# PIC32CM1216MC00048 register map
Vendor: Microchip Technology; Series: PIC32CMMC00; File version: 0
CPU: CM0+ r0p0, selectable endian, MPU, no FPU, 2 interrupt priority bits
Registers are 32-bit, read-write, reset 0x0 unless marked. A register's access mark holds for its fields unless they carry their own. Offsets are from the block's base; [hi:lo] are bit positions; {n}, {i} and the like mark numbered series; 'fields as' and 'values as' point back to an identical list.

## DSU — Device Service Unit
Base 0x41002000; register names take the prefix DSU_
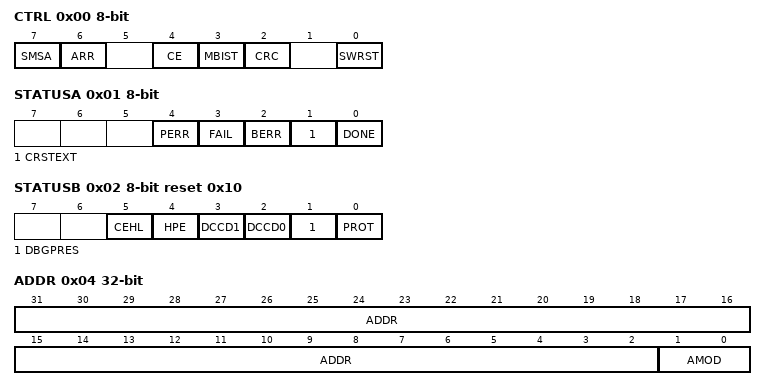
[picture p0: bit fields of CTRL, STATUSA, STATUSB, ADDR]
0x00 CTRL 8-bit wo — Control
  [7] SMSA — Start Memory Stream Access
  [6] ARR — Auxiliary Row Read
  [4] CE — Chip-Erase
  [3] MBIST — Memory built-in self-test
  [2] CRC — 32-bit Cyclic Redundancy Code
  [0] SWRST — Software Reset
0x01 STATUSA 8-bit
  [4] PERR — Protection Error
  [3] FAIL — Failure
  [2] BERR — Bus Error
  [1] CRSTEXT — CPU Reset Phase Extension
  [0] DONE
0x02 STATUSB 8-bit ro reset 0x10
  [5] CEHL — Chip Erase Hard Lock
  [4] HPE — Hot-Plugging Enable
  [3] DCCD1 — Debug Communication Channel 1 Dirty
  [2] DCCD0 — Debug Communication Channel 0 Dirty
  [1] DBGPRES — Debugger Present
  [0] PROT — Protected
0x03 STATUSC 8-bit ro
  [2:0] STATE
0x04 ADDR — Address
  [31:2] ADDR — Address
  [1:0] AMOD — Access Mode
0x08 LENGTH
  [31:2] LENGTH
0x0C DATA
{0x10+4i} DCC[{i}] (i=0..1) — Debug Communication Channel n
  [31:0] DATA
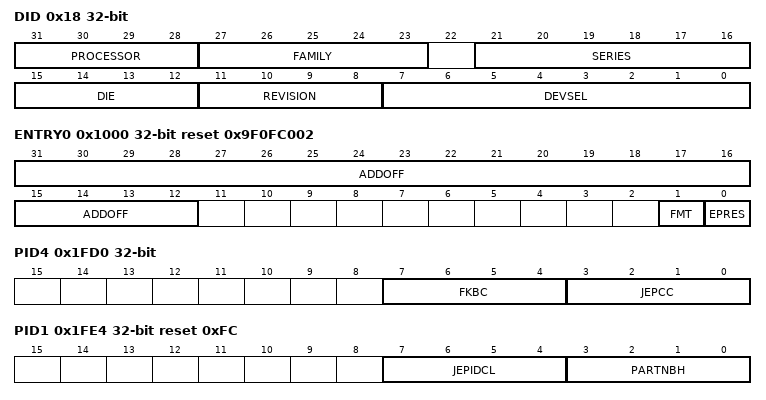
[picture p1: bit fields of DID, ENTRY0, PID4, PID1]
0x18 DID ro — Device Identification
  [31:28] PROCESSOR
    1=Cortex-M0+
  [27:23] FAMILY
    2=5V Industrial
  [21:16] SERIES
    6=MC00 (PIC32CM MC00)
  [15:12] DIE — Die Number
  [11:8] REVISION — Revision Number
  [7:0] DEVSEL — Device Select
    0=128KB_16KB_32PIN (128 KB Flash / 16 KB SRAM / 32-pin); 1=64KB_8KB_32PIN (64 KB Flash / 8 KB SRAM / 32-pin); 6=128KB_16KB_48PIN_CAN (128 KB Flash / 16 KB SRAM / 48-pin); 7=64KB_8KB_48PIN_CAN (64 KB Flash / 8 KB SRAM / 48-pin)
{0xF0+4i} DCFG[{i}] (i=0..1) — Device Configuration
  [31:0] DCFG
0x1000 ENTRY0 ro reset 0x9F0FC002 — CoreSight ROM Table Entry 0
  [31:12] ADDOFF — Address Offset
  [1] FMT — Format
  [0] EPRES — Entry Present
0x1004 ENTRY1 ro reset 0x5002 — CoreSight ROM Table Entry 1
0x1008 END ro — CoreSight ROM Table End
  [31:0] END — End Marker
0x1FCC MEMTYPE ro — CoreSight ROM Table Memory Type
  [0] SMEMP — System Memory Present
0x1FD0 PID4 ro — Peripheral Identification 4
  [7:4] FKBC — 4KB count
  [3:0] JEPCC — JEP-106 Continuation Code
{0x1FC0+4i} PID{i} ro (i=5..7) — Peripheral Identification {i}
0x1FE0 PID0 ro reset 0xD0 — Peripheral Identification 0
  [7:0] PARTNBL — Part Number Low
0x1FE4 PID1 ro reset 0xFC — Peripheral Identification 1
  [7:4] JEPIDCL — Low part of the JEP-106 Identity Code
  [3:0] PARTNBH — Part Number High
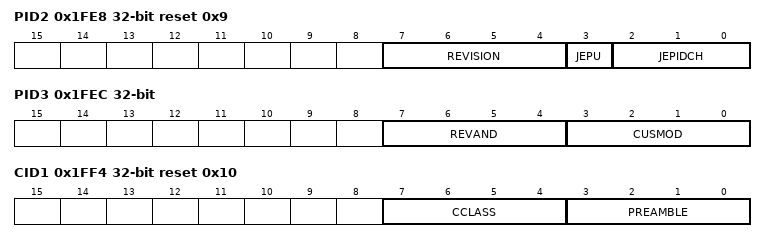
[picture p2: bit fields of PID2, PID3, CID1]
0x1FE8 PID2 ro reset 0x9 — Peripheral Identification 2
  [7:4] REVISION — Revision Number
  [3] JEPU — JEP-106 Identity Code is used
  [2:0] JEPIDCH — JEP-106 Identity Code High
0x1FEC PID3 ro — Peripheral Identification 3
  [7:4] REVAND — Revision Number
  [3:0] CUSMOD — ARM CUSMOD
0x1FF0 CID0 ro reset 0xD — Component Identification 0
  [7:0] PREAMBLEB0 — Preamble Byte 0
0x1FF4 CID1 ro reset 0x10 — Component Identification 1
  [7:4] CCLASS — Component Class
  [3:0] PREAMBLE
0x1FF8 CID2 ro reset 0x5 — Component Identification 2
  [7:0] PREAMBLEB2 — Preamble Byte 2
0x1FFC CID3 ro reset 0xB1 — Component Identification 3
  [7:0] PREAMBLEB3 — Preamble Byte 3

## EIC — External Interrupt Controller
Base 0x40002800; register names take the prefix EIC_
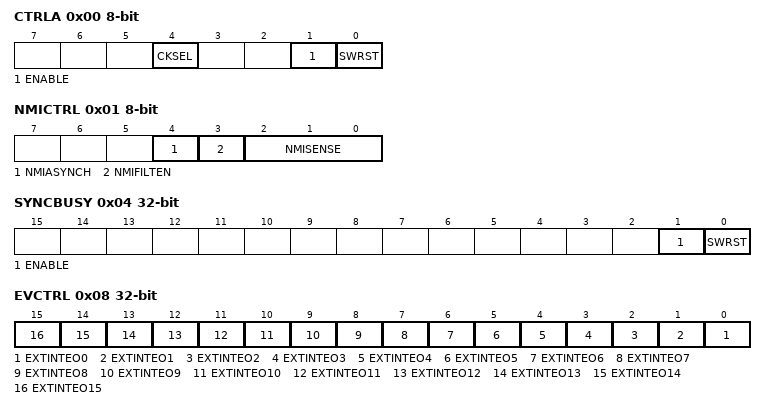
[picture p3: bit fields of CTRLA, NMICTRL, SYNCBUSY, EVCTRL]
0x00 CTRLA 8-bit — Control A
  [4] CKSEL — Clock Selection
    0=CLK_GCLK (Clocked by GCLK); 1=CLK_ULP32K (Clocked by ULP32K)
  [1] ENABLE
  [0] SWRST — Software Reset
0x01 NMICTRL 8-bit — Non-Maskable Interrupt Control
  [4] NMIASYNCH — Asynchronous Edge Detection Mode
    0=SYNC (Edge detection is clock synchronously operated); 1=ASYNC (Edge detection is clock asynchronously operated)
  [3] NMIFILTEN — Non-Maskable Interrupt Filter Enable
  [2:0] NMISENSE — Non-Maskable Interrupt Sense Configuration
    0=NONE (No detection); 1=RISE (Rising-edge detection); 2=FALL (Falling-edge detection); 3=BOTH (Both-edges detection); 4=HIGH (High-level detection); 5=LOW (Low-level detection)
0x02 NMIFLAG 16-bit — Non-Maskable Interrupt Flag Status and Clear
  [0] NMI — Non-Maskable Interrupt
0x04 SYNCBUSY ro — Synchronization Busy
  [1] ENABLE — Enable Synchronization Busy Status
  [0] SWRST — Software Reset Synchronization Busy Status
0x08 EVCTRL — Event Control
  [n] EXTINTEO{n} (n=0..15) — External Interrupt {n} Event Output Enable
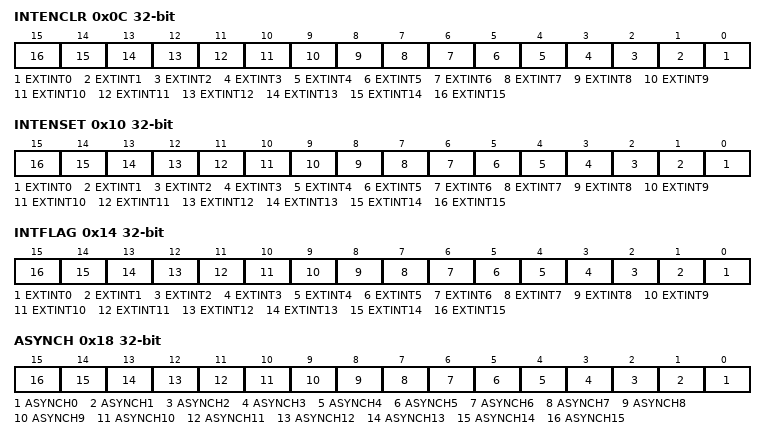
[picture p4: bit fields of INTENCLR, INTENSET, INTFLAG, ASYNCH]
0x0C INTENCLR — Interrupt Enable Clear
  [n] EXTINT{n} (n=0..15) — External Interrupt {n} Enable
0x10 INTENSET — Interrupt Enable Set
  [n] EXTINT{n} (n=0..15) — External Interrupt {n} Enable
0x14 INTFLAG — Interrupt Flag Status and Clear
  [n] EXTINT{n} (n=0..15) — External Interrupt {n}
0x18 ASYNCH — External Interrupt Asynchronous Mode
  [all] fields
    values as NMICTRL.NMIASYNCH
  [n] ASYNCH{n} (n=0..15) — Asynchronous Edge Detection Mode of EXTINT{n}
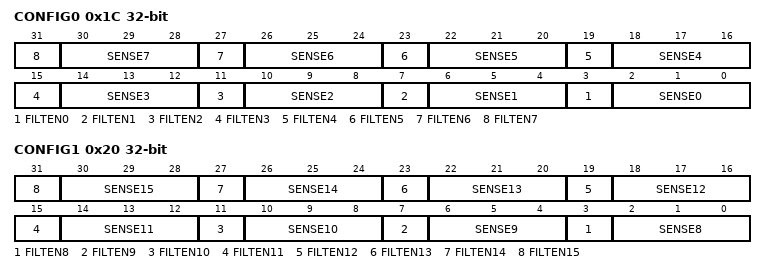
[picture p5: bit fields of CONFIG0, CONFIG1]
0x1C CONFIG0 — External Interrupt Sense Configuration
  [4n+3] FILTEN{n} (n=0..7) — Filter Enable {n}
  [4n+2:4n] SENSE{n} (n=0..7) — Input Sense Configuration {n}
    0=NONE (No detection); 1=RISE (Rising edge detection); 2=FALL (Falling edge detection); 3=BOTH (Both edges detection); 4=HIGH (High level detection); 5=LOW (Low level detection)
0x20 CONFIG1 — External Interrupt Sense Configuration
  [4n-29] FILTEN{n} (n=8..15) — Filter Enable {n}
  [4n-30:4n-32] SENSE{n} (n=8..15) — Input Sense Configuration {n}
    values as CONFIG0.SENSE0

## Notices in the file
Copyright (c) 2017 Microchip Technology Inc.
SPDX-License-Identifier: Apache-2.0
Licensed under the Apache License, Version 2.0 (the "License");
you may not use this file except in compliance with the License.
You may obtain a copy of the License at
http://www.apache.org/licenses/LICENSE-2.0
Unless required by applicable law or agreed to in writing, software
distributed under the License is distributed on an "AS IS" BASIS,
WITHOUT WARRANTIES OR CONDITIONS OF ANY KIND, either express or implied.
See the License for the specific language governing permissions and
limitations under the License.
